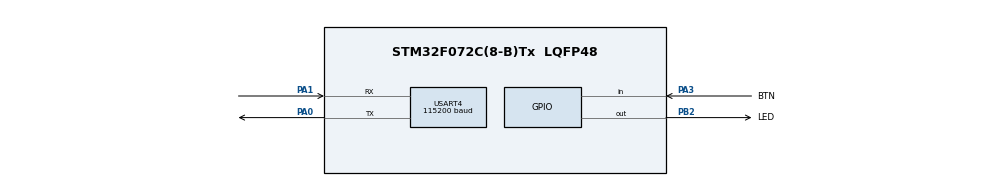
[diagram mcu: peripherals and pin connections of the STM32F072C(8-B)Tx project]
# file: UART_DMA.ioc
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Dma.Request0=USART4_RX
Dma.Request1=USART4_TX
Dma.USART4_RX.0.Direction=DMA_PERIPH_TO_MEMORY
Dma.USART4_RX.0.Instance=DMA1_Channel6
Dma.USART4_RX.0.MemDataAlignment=DMA_MDATAALIGN_BYTE
Dma.USART4_RX.0.MemInc=DMA_MINC_ENABLE
Dma.USART4_RX.0.Mode=DMA_NORMAL
Dma.USART4_RX.0.PeriphDataAlignment=DMA_PDATAALIGN_BYTE
Dma.USART4_RX.0.PeriphInc=DMA_PINC_DISABLE
Dma.USART4_RX.0.Priority=DMA_PRIORITY_LOW
Dma.USART4_TX.1.Direction=DMA_MEMORY_TO_PERIPH
Dma.USART4_TX.1.Instance=DMA1_Channel7
Dma.USART4_TX.1.MemDataAlignment=DMA_MDATAALIGN_BYTE
Dma.USART4_TX.1.MemInc=DMA_MINC_ENABLE
Dma.USART4_TX.1.Mode=DMA_NORMAL
Dma.USART4_TX.1.PeriphDataAlignment=DMA_PDATAALIGN_BYTE
Dma.USART4_TX.1.PeriphInc=DMA_PINC_DISABLE
Dma.USART4_TX.1.Priority=DMA_PRIORITY_LOW
Mcu.Family=STM32F0
Mcu.Name=STM32F072C(8-B)Tx
Mcu.Package=LQFP48
NVIC.DMA1_Channel4_5_6_7_IRQn=true\:0\:0\:false\:false\:true\:false\:true
NVIC.USART3_4_IRQn=true\:0\:0\:false\:false\:true\:true\:true
PA0.Mode=Asynchronous
PA0.Signal=USART4_TX
PA1.Mode=Asynchronous
PA1.Signal=USART4_RX
PA3.GPIO_Label=BTN
PA3.Signal=GPIO_Input
PB2.GPIO_Label=LED
PB2.Signal=GPIO_Output
ProjectManager.HeapSize=0x200
ProjectManager.StackSize=0x400
ProjectManager.TargetToolchain=STM32CubeIDE
USART4.BaudRate=115200
USART4.Parity=PARITY_EVEN
USART4.VirtualMode-Asynchronous=VM_ASYNC
USART4.WordLength=WORDLENGTH_9B
board=custom

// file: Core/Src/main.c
/* USER CODE BEGIN Header */
/**
  ******************************************************************************
  * @file           : main.c
  * @brief          : Main program body
  ******************************************************************************
  * @attention
  *
  * <h2><center>&copy; Copyright (c) 2021 STMicroelectronics.
  * All rights reserved.</center></h2>
  *
  * This software component is licensed by ST under BSD 3-Clause license,
  * the "License"; You may not use this file except in compliance with the
  * License. You may obtain a copy of the License at:
  *                        opensource.org/licenses/BSD-3-Clause
  *
  ******************************************************************************
  */
/* USER CODE END Header */
#include "main.h"

UART_HandleTypeDef huart4;
DMA_HandleTypeDef hdma_usart4_rx;
DMA_HandleTypeDef hdma_usart4_tx;

/* USER CODE BEGIN PV */
int btn_prev = 0; /*предыдущее состояние кнопки*/
int btn_cur = 0;/*текущее состояние кнопки*/
uint8_t RxData[1];/*Массив данных (1 элемент), которые будем считывать с ПК*/
char TxData[]="Subscribe to Amigo Electric YouTube Channel!\n";/*Массив данных, который будем отправлять на ПК*/
/* USER CODE END PV */

void SystemClock_Config(void);
static void MX_GPIO_Init(void);
static void MX_DMA_Init(void);
static void MX_USART4_UART_Init(void);

int main(void)
{

  /* MCU Configuration--------------------------------------------------------*/

  /* Reset of all peripherals, Initializes the Flash interface and the Systick. */
  HAL_Init();

  /* Configure the system clock */
  SystemClock_Config();

  /* Initialize all configured peripherals */
  MX_GPIO_Init();
  MX_DMA_Init();
  MX_USART4_UART_Init();

  /* Infinite loop */
  /* USER CODE BEGIN WHILE */
  while (1)
  {

	  btn_cur = HAL_GPIO_ReadPin(BTN_GPIO_Port, BTN_Pin);/*Считываем состояние кнопки*/
	  if ((btn_prev == 0) && (btn_cur != 0))/*Если предыдущие состояние 0,
	т.е. кнопка не была нажата, и текущее состояние не равно 0, т.е. кнопка нажата*/ {
		  HAL_UART_Transmit_DMA(&huart4, (uint8_t *)TxData, sizeof(TxData));/*Передадим массив TxData
	с контроллера на персональный компьютер*/
	  }
	  btn_prev = btn_cur;/*Запоминаем текущее состояние кнопки, чтобы исключить ложное срабатывание передачи данных,
	если кнопка останется зажатой*/

	  if ((HAL_UART_Receive_DMA (&huart4, (uint8_t *)RxData, sizeof(RxData))==HAL_OK) &&  (RxData[0] == '1'))/*Если
	данные с компьютера на контроллер были успешно переданы и первый элемент массива равен 1, то*/ {
		  HAL_GPIO_TogglePin(LED_GPIO_Port, LED_Pin);/*Поменяем состояние светодиода*/
	  }

    /* USER CODE END WHILE */

  }
}

void SystemClock_Config(void)
{
  RCC_OscInitTypeDef RCC_OscInitStruct = {0};
  RCC_ClkInitTypeDef RCC_ClkInitStruct = {0};

  /** Initializes the RCC Oscillators according to the specified parameters
  * in the RCC_OscInitTypeDef structure.
  */
  RCC_OscInitStruct.OscillatorType = RCC_OSCILLATORTYPE_HSI;
  RCC_OscInitStruct.HSIState = RCC_HSI_ON;
  RCC_OscInitStruct.HSICalibrationValue = RCC_HSICALIBRATION_DEFAULT;
  RCC_OscInitStruct.PLL.PLLState = RCC_PLL_NONE;
  if (HAL_RCC_OscConfig(&RCC_OscInitStruct) != HAL_OK)
  {
    Error_Handler();
  }
  /** Initializes the CPU, AHB and APB buses clocks
  */
  RCC_ClkInitStruct.ClockType = RCC_CLOCKTYPE_HCLK|RCC_CLOCKTYPE_SYSCLK
                              |RCC_CLOCKTYPE_PCLK1;
  RCC_ClkInitStruct.SYSCLKSource = RCC_SYSCLKSOURCE_HSI;
  RCC_ClkInitStruct.AHBCLKDivider = RCC_SYSCLK_DIV1;
  RCC_ClkInitStruct.APB1CLKDivider = RCC_HCLK_DIV1;

  if (HAL_RCC_ClockConfig(&RCC_ClkInitStruct, FLASH_LATENCY_0) != HAL_OK)
  {
    Error_Handler();
  }
}

static void MX_USART4_UART_Init(void)
{

  huart4.Instance = USART4;
  huart4.Init.BaudRate = 115200;
  huart4.Init.WordLength = UART_WORDLENGTH_9B;
  huart4.Init.StopBits = UART_STOPBITS_1;
  huart4.Init.Parity = UART_PARITY_EVEN;
  huart4.Init.Mode = UART_MODE_TX_RX;
  huart4.Init.HwFlowCtl = UART_HWCONTROL_NONE;
  huart4.Init.OverSampling = UART_OVERSAMPLING_16;
  huart4.Init.OneBitSampling = UART_ONE_BIT_SAMPLE_DISABLE;
  huart4.AdvancedInit.AdvFeatureInit = UART_ADVFEATURE_NO_INIT;
  if (HAL_UART_Init(&huart4) != HAL_OK)
  {
    Error_Handler();
  }

}

static void MX_DMA_Init(void)
{

  /* DMA controller clock enable */
  __HAL_RCC_DMA1_CLK_ENABLE();

  /* DMA interrupt init */
  /* DMA1_Channel4_5_6_7_IRQn interrupt configuration */
  HAL_NVIC_SetPriority(DMA1_Channel4_5_6_7_IRQn, 0, 0);
  HAL_NVIC_EnableIRQ(DMA1_Channel4_5_6_7_IRQn);

}

static void MX_GPIO_Init(void)
{
  GPIO_InitTypeDef GPIO_InitStruct = {0};

  /* GPIO Ports Clock Enable */
  __HAL_RCC_GPIOA_CLK_ENABLE();
  __HAL_RCC_GPIOB_CLK_ENABLE();

  /*Configure GPIO pin Output Level */
  HAL_GPIO_WritePin(LED_GPIO_Port, LED_Pin, GPIO_PIN_RESET);

  /*Configure GPIO pin : BTN_Pin */
  GPIO_InitStruct.Pin = BTN_Pin;
  GPIO_InitStruct.Mode = GPIO_MODE_INPUT;
  GPIO_InitStruct.Pull = GPIO_NOPULL;
  HAL_GPIO_Init(BTN_GPIO_Port, &GPIO_InitStruct);

  /*Configure GPIO pin : LED_Pin */
  GPIO_InitStruct.Pin = LED_Pin;
  GPIO_InitStruct.Mode = GPIO_MODE_OUTPUT_PP;
  GPIO_InitStruct.Pull = GPIO_NOPULL;
  GPIO_InitStruct.Speed = GPIO_SPEED_FREQ_LOW;
  HAL_GPIO_Init(LED_GPIO_Port, &GPIO_InitStruct);

}

void Error_Handler(void)
{
  __disable_irq();
  while (1)
  {
  }
}

/************************ (C) COPYRIGHT STMicroelectronics *****END OF FILE****/
